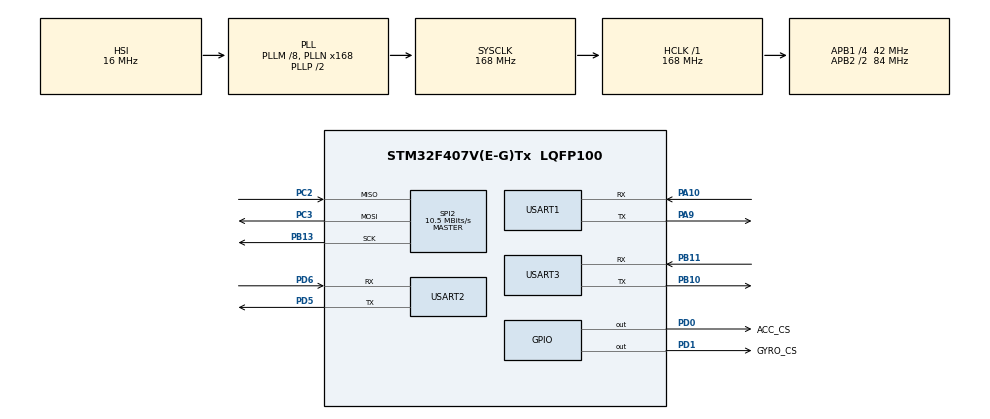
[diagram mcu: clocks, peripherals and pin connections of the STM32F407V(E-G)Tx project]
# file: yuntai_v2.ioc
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Dma.MEMTOMEM.2.Direction=DMA_MEMORY_TO_MEMORY
Dma.MEMTOMEM.2.FIFOMode=DMA_FIFOMODE_ENABLE
Dma.MEMTOMEM.2.FIFOThreshold=DMA_FIFO_THRESHOLD_FULL
Dma.MEMTOMEM.2.Instance=DMA2_Stream0
Dma.MEMTOMEM.2.MemBurst=DMA_MBURST_SINGLE
Dma.MEMTOMEM.2.MemDataAlignment=DMA_MDATAALIGN_BYTE
Dma.MEMTOMEM.2.MemInc=DMA_MINC_ENABLE
Dma.MEMTOMEM.2.Mode=DMA_NORMAL
Dma.MEMTOMEM.2.PeriphBurst=DMA_PBURST_SINGLE
Dma.MEMTOMEM.2.PeriphDataAlignment=DMA_PDATAALIGN_BYTE
Dma.MEMTOMEM.2.PeriphInc=DMA_PINC_ENABLE
Dma.MEMTOMEM.2.Priority=DMA_PRIORITY_LOW
Dma.Request0=USART1_RX
Dma.Request1=USART1_TX
Dma.Request2=MEMTOMEM
Dma.Request3=SPI2_RX
Dma.Request4=SPI2_TX
Dma.SPI2_RX.3.Direction=DMA_PERIPH_TO_MEMORY
Dma.SPI2_RX.3.FIFOMode=DMA_FIFOMODE_DISABLE
Dma.SPI2_RX.3.Instance=DMA1_Stream3
Dma.SPI2_RX.3.MemDataAlignment=DMA_MDATAALIGN_BYTE
Dma.SPI2_RX.3.MemInc=DMA_MINC_ENABLE
Dma.SPI2_RX.3.Mode=DMA_NORMAL
Dma.SPI2_RX.3.PeriphDataAlignment=DMA_PDATAALIGN_BYTE
Dma.SPI2_RX.3.PeriphInc=DMA_PINC_DISABLE
Dma.SPI2_RX.3.Priority=DMA_PRIORITY_VERY_HIGH
Dma.SPI2_TX.4.Direction=DMA_MEMORY_TO_PERIPH
Dma.SPI2_TX.4.FIFOMode=DMA_FIFOMODE_DISABLE
Dma.SPI2_TX.4.Instance=DMA1_Stream4
Dma.SPI2_TX.4.MemDataAlignment=DMA_MDATAALIGN_BYTE
Dma.SPI2_TX.4.MemInc=DMA_MINC_ENABLE
Dma.SPI2_TX.4.Mode=DMA_NORMAL
Dma.SPI2_TX.4.PeriphDataAlignment=DMA_PDATAALIGN_BYTE
Dma.SPI2_TX.4.PeriphInc=DMA_PINC_DISABLE
Dma.SPI2_TX.4.Priority=DMA_PRIORITY_HIGH
Dma.USART1_RX.0.Direction=DMA_PERIPH_TO_MEMORY
Dma.USART1_RX.0.FIFOMode=DMA_FIFOMODE_DISABLE
Dma.USART1_RX.0.Instance=DMA2_Stream2
Dma.USART1_RX.0.MemDataAlignment=DMA_MDATAALIGN_BYTE
Dma.USART1_RX.0.MemInc=DMA_MINC_ENABLE
Dma.USART1_RX.0.Mode=DMA_CIRCULAR
Dma.USART1_RX.0.PeriphDataAlignment=DMA_PDATAALIGN_BYTE
Dma.USART1_RX.0.PeriphInc=DMA_PINC_DISABLE
Dma.USART1_RX.0.Priority=DMA_PRIORITY_HIGH
Dma.USART1_TX.1.Direction=DMA_MEMORY_TO_PERIPH
Dma.USART1_TX.1.FIFOMode=DMA_FIFOMODE_DISABLE
Dma.USART1_TX.1.Instance=DMA2_Stream7
Dma.USART1_TX.1.MemDataAlignment=DMA_MDATAALIGN_BYTE
Dma.USART1_TX.1.MemInc=DMA_MINC_ENABLE
Dma.USART1_TX.1.Mode=DMA_NORMAL
Dma.USART1_TX.1.PeriphDataAlignment=DMA_PDATAALIGN_BYTE
Dma.USART1_TX.1.PeriphInc=DMA_PINC_DISABLE
Dma.USART1_TX.1.Priority=DMA_PRIORITY_HIGH
FREERTOS.Tasks01=defaultTask,24,128,StartDefaultTask,Default,NULL,Dynamic,NULL,NULL
Mcu.Family=STM32F4
Mcu.Name=STM32F407V(E-G)Tx
Mcu.Package=LQFP100
NVIC.DMA1_Stream3_IRQn=true\:5\:0\:false\:false\:true\:true\:false\:true\:true
NVIC.DMA1_Stream4_IRQn=true\:5\:0\:false\:false\:true\:true\:false\:true\:true
NVIC.DMA2_Stream2_IRQn=true\:5\:0\:false\:false\:true\:true\:false\:true\:true
NVIC.DMA2_Stream7_IRQn=true\:5\:0\:false\:false\:true\:true\:false\:true\:true
NVIC.PriorityGroup=NVIC_PRIORITYGROUP_4
NVIC.SPI2_IRQn=true\:5\:0\:false\:false\:true\:true\:true\:true\:true
NVIC.TIM6_DAC_IRQn=true\:15\:0\:false\:false\:true\:false\:false\:true\:true
NVIC.TimeBase=TIM6_DAC_IRQn
NVIC.TimeBaseIP=TIM6
NVIC.USART1_IRQn=true\:5\:0\:false\:false\:true\:true\:true\:true\:true
NVIC.USART2_IRQn=true\:5\:0\:false\:false\:true\:true\:true\:true\:true
NVIC.USART3_IRQn=true\:5\:0\:false\:false\:true\:true\:true\:true\:true
PA10.Mode=Asynchronous
PA10.Signal=USART1_RX
PA13.Mode=Serial_Wire
PA13.Signal=SYS_JTMS-SWDIO
PA14.Mode=Serial_Wire
PA14.Signal=SYS_JTCK-SWCLK
PA9.Mode=Asynchronous
PA9.Signal=USART1_TX
PB10.Mode=Asynchronous
PB10.Signal=USART3_TX
PB11.Mode=Asynchronous
PB11.Signal=USART3_RX
PB13.Mode=Full_Duplex_Master
PB13.Signal=SPI2_SCK
PC2.Mode=Full_Duplex_Master
PC2.Signal=SPI2_MISO
PC3.Mode=Full_Duplex_Master
PC3.Signal=SPI2_MOSI
PD0.GPIO_Label=ACC_CS
PD0.GPIO_Speed=GPIO_SPEED_FREQ_VERY_HIGH
PD0.PinState=GPIO_PIN_SET
PD0.Signal=GPIO_Output
PD1.GPIO_Label=GYRO_CS
PD1.GPIO_PuPd=GPIO_NOPULL
PD1.GPIO_Speed=GPIO_SPEED_FREQ_VERY_HIGH
PD1.PinState=GPIO_PIN_SET
PD1.Signal=GPIO_Output
PD5.Mode=Asynchronous
PD5.Signal=USART2_TX
PD6.Mode=Asynchronous
PD6.Signal=USART2_RX
PH0-OSC_IN.Mode=HSE-External-Oscillator
PH0-OSC_IN.Signal=RCC_OSC_IN
PH1-OSC_OUT.Mode=HSE-External-Oscillator
PH1-OSC_OUT.Signal=RCC_OSC_OUT
ProjectManager.HeapSize=0x200
ProjectManager.StackSize=0x400
ProjectManager.TargetToolchain=CMake
RCC.48MHZClocksFreq_Value=84000000
RCC.AHBFreq_Value=168000000
RCC.APB1CLKDivider=RCC_HCLK_DIV4
RCC.APB1Freq_Value=42000000
RCC.APB1TimFreq_Value=84000000
RCC.APB2CLKDivider=RCC_HCLK_DIV2
RCC.APB2Freq_Value=84000000
RCC.APB2TimFreq_Value=168000000
RCC.CortexFreq_Value=168000000
RCC.HCLKFreq_Value=168000000
RCC.HSE_VALUE=8000000
RCC.HSI_VALUE=16000000
RCC.LSE_VALUE=32768
RCC.PLLM=8
RCC.PLLN=168
RCC.SYSCLKFreq_VALUE=168000000
RCC.SYSCLKSource=RCC_SYSCLKSOURCE_PLLCLK
RCC.VCOOutputFreq_Value=336000000
SPI2.BaudRatePrescaler=SPI_BAUDRATEPRESCALER_4
SPI2.CLKPhase=SPI_PHASE_2EDGE
SPI2.CLKPolarity=SPI_POLARITY_HIGH
SPI2.CalculateBaudRate=10.5 MBits/s
SPI2.Direction=SPI_DIRECTION_2LINES
SPI2.Mode=SPI_MODE_MASTER
SPI2.VirtualType=VM_MASTER
USART1.VirtualMode=VM_ASYNC
USART2.VirtualMode=VM_ASYNC
USART3.VirtualMode=VM_ASYNC
VP_FREERTOS_VS_CMSIS_V2.Mode=CMSIS_V2
VP_SYS_VS_tim6.Mode=TIM6
board=custom

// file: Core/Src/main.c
/* USER CODE BEGIN Header */
/**
  ******************************************************************************
  * @file           : main.c
  * @brief          : Main program body
  ******************************************************************************
  * @attention
  *
  * Copyright (c) 2026 STMicroelectronics.
  * All rights reserved.
  *
  * This software is licensed under terms that can be found in the LICENSE file
  * in the root directory of this software component.
  * If no LICENSE file comes with this software, it is provided AS-IS.
  *
  ******************************************************************************
  */
/* USER CODE END Header */
#include "main.h"
#include "cmsis_os.h"
#include "dma.h"
#include "spi.h"
#include "usart.h"
#include "gpio.h"

void SystemClock_Config(void);
void MX_FREERTOS_Init(void);

int main(void)
{

  /* MCU Configuration--------------------------------------------------------*/

  /* Reset of all peripherals, Initializes the Flash interface and the Systick. */
  HAL_Init();

  /* Configure the system clock */
  SystemClock_Config();

  /* Initialize all configured peripherals */
  MX_GPIO_Init();
  MX_DMA_Init();
  MX_SPI2_Init();
  MX_USART1_UART_Init();
  MX_USART2_UART_Init();
  MX_USART3_UART_Init();

  /* Init scheduler */
  osKernelInitialize();  /* Call init function for freertos objects (in cmsis_os2.c) */
  MX_FREERTOS_Init();

  /* Start scheduler */
  osKernelStart();

  /* We should never get here as control is now taken by the scheduler */

  /* Infinite loop */
  while (1)
  {

  }
}

void SystemClock_Config(void)
{
  RCC_OscInitTypeDef RCC_OscInitStruct = {0};
  RCC_ClkInitTypeDef RCC_ClkInitStruct = {0};

  /** Configure the main internal regulator output voltage
  */
  __HAL_RCC_PWR_CLK_ENABLE();
  __HAL_PWR_VOLTAGESCALING_CONFIG(PWR_REGULATOR_VOLTAGE_SCALE1);

  /** Initializes the RCC Oscillators according to the specified parameters
  * in the RCC_OscInitTypeDef structure.
  */
  RCC_OscInitStruct.OscillatorType = RCC_OSCILLATORTYPE_HSI;
  RCC_OscInitStruct.HSIState = RCC_HSI_ON;
  RCC_OscInitStruct.HSICalibrationValue = RCC_HSICALIBRATION_DEFAULT;
  RCC_OscInitStruct.PLL.PLLState = RCC_PLL_ON;
  RCC_OscInitStruct.PLL.PLLSource = RCC_PLLSOURCE_HSI;
  RCC_OscInitStruct.PLL.PLLM = 8;
  RCC_OscInitStruct.PLL.PLLN = 168;
  RCC_OscInitStruct.PLL.PLLP = RCC_PLLP_DIV2;
  RCC_OscInitStruct.PLL.PLLQ = 4;
  if (HAL_RCC_OscConfig(&RCC_OscInitStruct) != HAL_OK)
  {
    Error_Handler();
  }

  /** Initializes the CPU, AHB and APB buses clocks
  */
  RCC_ClkInitStruct.ClockType = RCC_CLOCKTYPE_HCLK|RCC_CLOCKTYPE_SYSCLK
                              |RCC_CLOCKTYPE_PCLK1|RCC_CLOCKTYPE_PCLK2;
  RCC_ClkInitStruct.SYSCLKSource = RCC_SYSCLKSOURCE_PLLCLK;
  RCC_ClkInitStruct.AHBCLKDivider = RCC_SYSCLK_DIV1;
  RCC_ClkInitStruct.APB1CLKDivider = RCC_HCLK_DIV4;
  RCC_ClkInitStruct.APB2CLKDivider = RCC_HCLK_DIV2;

  if (HAL_RCC_ClockConfig(&RCC_ClkInitStruct, FLASH_LATENCY_5) != HAL_OK)
  {
    Error_Handler();
  }
}

void HAL_TIM_PeriodElapsedCallback(TIM_HandleTypeDef *htim)
{
  if (htim->Instance == TIM6)
  {
    HAL_IncTick();
  }
}

void Error_Handler(void)
{
  __disable_irq();
  while (1)
  {
  }
}

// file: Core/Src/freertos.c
/* USER CODE BEGIN Header */
/**
  ******************************************************************************
  * File Name          : freertos.c
  * Description        : Code for freertos applications
  ******************************************************************************
  * @attention
  *
  * Copyright (c) 2026 STMicroelectronics.
  * All rights reserved.
  *
  * This software is licensed under terms that can be found in the LICENSE file
  * in the root directory of this software component.
  * If no LICENSE file comes with this software, it is provided AS-IS.
  *
  ******************************************************************************
  */
/* USER CODE END Header */

#include "FreeRTOS.h"
#include "task.h"
#include "main.h"
#include "cmsis_os.h"

/* USER CODE BEGIN Includes */
#include "imu_task.hpp"
/* USER CODE END Includes */

/* Definitions for defaultTask */
osThreadId_t defaultTaskHandle;
const osThreadAttr_t defaultTask_attributes = {
  .name = "defaultTask",
  .stack_size = 128 * 4,
  .priority = (osPriority_t) osPriorityNormal,
};

void StartDefaultTask(void *argument);

void MX_FREERTOS_Init(void); /* (MISRA C 2004 rule 8.1) */

void MX_FREERTOS_Init(void) {

  /* Create the thread(s) */
  /* creation of defaultTask */
  defaultTaskHandle = osThreadNew(StartDefaultTask, NULL, &defaultTask_attributes);

}

void StartDefaultTask(void *argument)
{
  /* USER CODE BEGIN StartDefaultTask */
  appImuTask(argument);
  /* USER CODE END StartDefaultTask */
}
